# ATSAMA5D27 register map
Vendor: Microchip Technology Inc.; File version: 1.0
CPU: CA5 r0p1, little endian, no MPU, no FPU, 4 interrupt priority bits
Address unit: 32 bits
Registers are 32-bit, read-write, reset 0x0 unless marked. A register's access mark holds for its fields unless they carry their own. Offsets are from the block's base; [hi:lo] are bit positions; 'fields as' and 'values as' point back to an identical list.

## SSC0 — Synchronous Serial Controller
Base 0xF8004000
Same registers: SSC1 0xFC004000
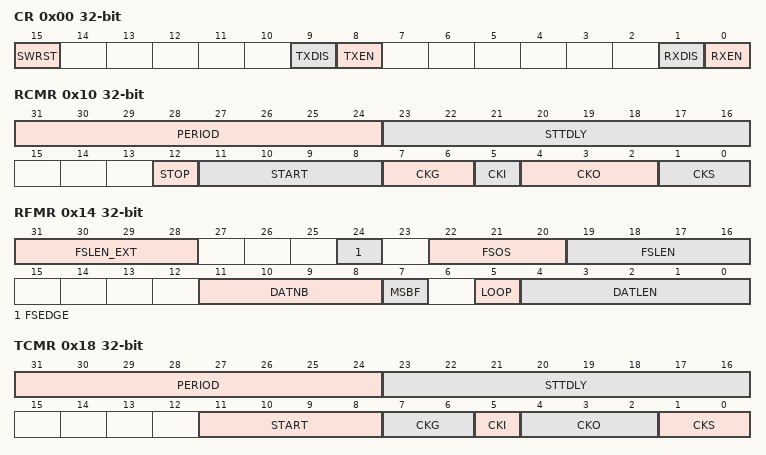
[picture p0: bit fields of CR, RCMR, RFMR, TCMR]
0x00 CR wo — Control Register
  [15] SWRST rw — Software Reset
  [9] TXDIS rw — Transmit Disable
  [8] TXEN rw — Transmit Enable
  [1] RXDIS rw — Receive Disable
  [0] RXEN rw — Receive Enable
0x04 CMR — Clock Mode Register
  [11:0] DIV — Clock Divider
0x10 RCMR — Receive Clock Mode Register
  [31:24] PERIOD — Receive Period Divider Selection
  [23:16] STTDLY — Receive Start Delay
  [12] STOP — Receive Stop Selection
  [11:8] START — Receive Start Selection
    0=CONTINUOUS (Continuous, as soon as the receiver is enabled, and immediately after the end of transfer of the previous data.); 1=TRANSMIT (Transmit start); 2=RF_LOW (Detection of a low level on RF signal); 3=RF_HIGH (Detection of a high level on RF signal); 4=RF_FALLING (Detection of a falling edge on RF signal); 5=RF_RISING (Detection of a rising edge on RF signal); 6=RF_LEVEL (Detection of any level change on RF signal); 7=RF_EDGE (Detection of any edge on RF signal); 8=CMP_0 (Compare 0)
  [7:6] CKG — Receive Clock Gating Selection
    0=CONTINUOUS (None); 1=EN_RF_LOW (Receive Clock enabled only if RF Low); 2=EN_RF_HIGH (Receive Clock enabled only if RF High)
  [5] CKI — Receive Clock Inversion
  [4:2] CKO — Receive Clock Output Mode Selection
    0=NONE (None, RK pin is an input); 1=CONTINUOUS (Continuous Receive Clock, RK pin is an output); 2=TRANSFER (Receive Clock only during data transfers, RK pin is an output)
  [1:0] CKS — Receive Clock Selection
    0=MCK (Divided Clock); 1=TK (TK Clock signal); 2=RK (RK pin)
0x14 RFMR — Receive Frame Mode Register
  [31:28] FSLEN_EXT — FSLEN Field Extension
  [24] FSEDGE — Frame Sync Edge Detection
    0=POSITIVE (Positive Edge Detection); 1=NEGATIVE (Negative Edge Detection)
  [22:20] FSOS — Receive Frame Sync Output Selection
    0=NONE (None, RF pin is an input); 1=NEGATIVE (Negative Pulse, RF pin is an output); 2=POSITIVE (Positive Pulse, RF pin is an output); 3=LOW (Driven Low during data transfer, RF pin is an output); 4=HIGH (Driven High during data transfer, RF pin is an output); 5=TOGGLING (Toggling at each start of data transfer, RF pin is an output)
  [19:16] FSLEN — Receive Frame Sync Length
  [11:8] DATNB — Data Number per Frame
  [7] MSBF — Most Significant Bit First
  [5] LOOP — Loop Mode
  [4:0] DATLEN — Data Length
0x18 TCMR — Transmit Clock Mode Register
  [31:24] PERIOD — Transmit Period Divider Selection
  [23:16] STTDLY — Transmit Start Delay
  [11:8] START — Transmit Start Selection
    0=CONTINUOUS (Continuous, as soon as a word is written in the SSC_THR (if Transmit is enabled), and immediately after the end of transfer of the previous data); 1=RECEIVE (Receive start); 2=TF_LOW (Detection of a low level on TF signal); 3=TF_HIGH (Detection of a high level on TF signal); 4=TF_FALLING (Detection of a falling edge on TF signal); 5=TF_RISING (Detection of a rising edge on TF signal); 6=TF_LEVEL (Detection of any level change on TF signal); 7=TF_EDGE (Detection of any edge on TF signal)
  [7:6] CKG — Transmit Clock Gating Selection
    0=CONTINUOUS (None); 1=EN_TF_LOW (Transmit Clock enabled only if TF Low); 2=EN_TF_HIGH (Transmit Clock enabled only if TF High)
  [5] CKI — Transmit Clock Inversion
  [4:2] CKO — Transmit Clock Output Mode Selection
    0=NONE (None, TK pin is an input); 1=CONTINUOUS (Continuous Transmit Clock, TK pin is an output); 2=TRANSFER (Transmit Clock only during data transfers, TK pin is an output)
  [1:0] CKS — Transmit Clock Selection
    0=MCK (Divided Clock); 1=RK (RK Clock signal); 2=TK (TK pin)
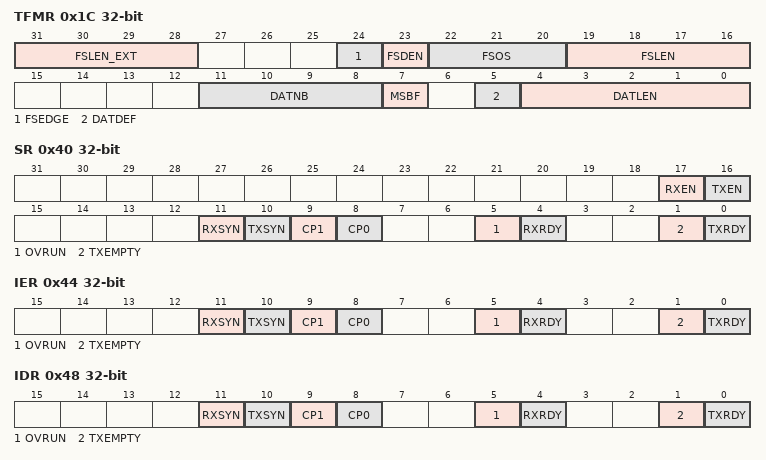
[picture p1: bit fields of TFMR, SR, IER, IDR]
0x1C TFMR — Transmit Frame Mode Register
  [31:28] FSLEN_EXT — FSLEN Field Extension
  [24] FSEDGE — Frame Sync Edge Detection
    values as RFMR.FSEDGE
  [23] FSDEN — Frame Sync Data Enable
  [22:20] FSOS — Transmit Frame Sync Output Selection
    0=NONE (None, TF pin is an input); 1=NEGATIVE (Negative Pulse, TF pin is an output); 2=POSITIVE (Positive Pulse, TF pin is an output); 3=LOW (Driven Low during data transfer); 4=HIGH (Driven High during data transfer); 5=TOGGLING (Toggling at each start of data transfer)
  [19:16] FSLEN — Transmit Frame Sync Length
  [11:8] DATNB — Data Number per Frame
  [7] MSBF — Most Significant Bit First
  [5] DATDEF — Data Default Value
  [4:0] DATLEN — Data Length
0x20 RHR ro — Receive Holding Register
  [31:0] RDAT rw — Receive Data
0x24 THR wo — Transmit Holding Register
  [31:0] TDAT rw — Transmit Data
0x30 RSHR ro — Receive Sync. Holding Register
  [15:0] RSDAT rw — Receive Synchronization Data
0x34 TSHR — Transmit Sync. Holding Register
  [15:0] TSDAT — Transmit Synchronization Data
0x38 RC0R — Receive Compare 0 Register
  [15:0] CP0 — Receive Compare Data 0
0x3C RC1R — Receive Compare 1 Register
  [15:0] CP1 — Receive Compare Data 1
0x40 SR ro — Status Register
  [17] RXEN rw — Receive Enable
  [16] TXEN rw — Transmit Enable
  [11] RXSYN rw — Receive Sync
  [10] TXSYN rw — Transmit Sync
  [9] CP1 rw — Compare 1
  [8] CP0 rw — Compare 0
  [5] OVRUN rw — Receive Overrun
  [4] RXRDY rw — Receive Ready
  [1] TXEMPTY rw — Transmit Empty
  [0] TXRDY rw — Transmit Ready
0x44 IER wo — Interrupt Enable Register
  [11] RXSYN rw — Rx Sync Interrupt Enable
  [10] TXSYN rw — Tx Sync Interrupt Enable
  [9] CP1 rw — Compare 1 Interrupt Enable
  [8] CP0 rw — Compare 0 Interrupt Enable
  [5] OVRUN rw — Receive Overrun Interrupt Enable
  [4] RXRDY rw — Receive Ready Interrupt Enable
  [1] TXEMPTY rw — Transmit Empty Interrupt Enable
  [0] TXRDY rw — Transmit Ready Interrupt Enable
0x48 IDR wo — Interrupt Disable Register
  [11] RXSYN rw — Rx Sync Interrupt Enable
  [10] TXSYN rw — Tx Sync Interrupt Enable
  [9] CP1 rw — Compare 1 Interrupt Disable
  [8] CP0 rw — Compare 0 Interrupt Disable
  [5] OVRUN rw — Receive Overrun Interrupt Disable
  [4] RXRDY rw — Receive Ready Interrupt Disable
  [1] TXEMPTY rw — Transmit Empty Interrupt Disable
  [0] TXRDY rw — Transmit Ready Interrupt Disable
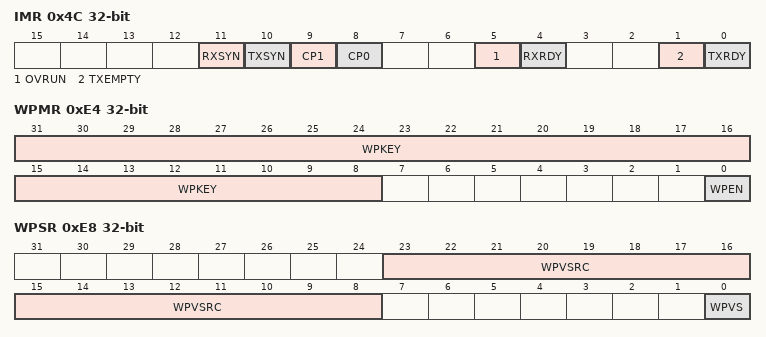
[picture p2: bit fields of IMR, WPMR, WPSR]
0x4C IMR ro — Interrupt Mask Register
  [11] RXSYN rw — Rx Sync Interrupt Mask
  [10] TXSYN rw — Tx Sync Interrupt Mask
  [9] CP1 rw — Compare 1 Interrupt Mask
  [8] CP0 rw — Compare 0 Interrupt Mask
  [5] OVRUN rw — Receive Overrun Interrupt Mask
  [4] RXRDY rw — Receive Ready Interrupt Mask
  [1] TXEMPTY rw — Transmit Empty Interrupt Mask
  [0] TXRDY rw — Transmit Ready Interrupt Mask
0xE4 WPMR — Write Protection Mode Register
  [31:8] WPKEY — Write Protection Key
    0x535343=PASSWD (Writing any other value in this field aborts the write operation of the WPEN bit.Always reads as 0.)
  [0] WPEN — Write Protection Enable
0xE8 WPSR ro — Write Protection Status Register
  [23:8] WPVSRC rw — Write Protect Violation Source
  [0] WPVS rw — Write Protection Violation Status
